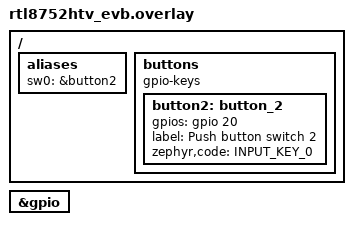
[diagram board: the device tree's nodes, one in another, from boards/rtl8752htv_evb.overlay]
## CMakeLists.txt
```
# SPDX-License-Identifier: Apache-2.0

cmake_minimum_required(VERSION 3.20.0)

find_package(Zephyr REQUIRED HINTS $ENV{ZEPHYR_BASE})
project(pad_wakeup_dlps)

FILE(GLOB app_sources src/*.c)
target_sources(app PRIVATE ${app_sources})
```

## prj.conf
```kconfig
CONFIG_PM=y
CONFIG_PM_DEVICE=y
CONFIG_PM_POLICY_CUSTOM=n # use zephyr pm flow, enable this config; use realtek pm flow, disable this config.
CONFIG_RUNTIME_NMI=y # customize NMI for Power Manager
CONFIG_REALTEK_USING_SDK_LIB=y
CONFIG_GPIO=y
CONFIG_ZTEST=y
```

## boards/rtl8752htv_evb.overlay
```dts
#include <zephyr/dt-bindings/input/input-event-codes.h>
/ {
	aliases {
		sw0 = &button2;
	};
    buttons {
		compatible = "gpio-keys";
		button2: button_2 {
			gpios = <&gpio 20 (GPIO_PULL_UP|GPIO_ACTIVE_HIGH)>;
			label = "Push button switch 2";
			zephyr,code = <INPUT_KEY_0>;
		};
	};
};

&gpio {
	status = "okay";
};
```

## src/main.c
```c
/*
 * Copyright (c) 2025 Realtek Semiconductor Corp.
 *
 * SPDX-License-Identifier: Apache-2.0
 */

#include <zephyr/kernel.h>
#include <zephyr/drivers/gpio.h>
#include <zephyr/ztest.h>

#if (CONFIG_SOC_SERIES_RTL8752H) /* CONFIG_SOC_SERIES_RTL8752H */
#include <zephyr/dt-bindings/gpio/realtek-bee-gpio.h>
#include <dlps.h>
#include <trace.h>
#include <rtl876x_pinmux.h>
#define power_get_statistics platform_pm_get_statistics
#else
#include <zephyr/dt-bindings/gpio/realtek-rtl87x2g-gpio.h>
#include <pm.h>
#endif

#define KEY_PRESS_NUMBERS 5
static uint32_t key_press_num;

static struct k_sem test_thread_sem;

static uint32_t wakeup_count_before_test;
static uint32_t wakeup_count_after_test;
static uint32_t last_wakeup_clk, last_sleep_clk;

#if DT_NODE_EXISTS(DT_NODELABEL(button2))
#define BUTTON DT_NODELABEL(button2)
#endif

#if DT_NODE_EXISTS(BUTTON)
#define BUTTON_DEV   DT_PHANDLE(BUTTON, gpios)
#define BUTTON_PIN   DT_PHA(BUTTON, gpios, pin)
#define BUTTON_FLAGS DT_PHA(BUTTON, gpios, flags)

static const struct device *const button_dev = DEVICE_DT_GET(BUTTON_DEV);

static struct k_work button_work;

static void button_cb(const struct device *port, struct gpio_callback *cb, gpio_port_pins_t pins)
{
	DBG_DIRECT("button_cb");
	k_work_submit(&button_work);
}
#endif /* BUTTON */

static void button_pressed(struct k_work *work)
{
	key_press_num++;
	printk("button press tested, key_press_num:%d!\n", key_press_num);
	if (key_press_num == KEY_PRESS_NUMBERS) {
		k_sem_give(&test_thread_sem);
	}
}

ZTEST(pad_wakeup_dlps, test_gpio_wakeup_dlps)
{
	printk("Starting gpio_wakeup_dlps Test\n");
	k_work_init(&button_work, button_pressed);
	int err;

	err = gpio_pin_configure(button_dev, BUTTON_PIN,
				 BUTTON_FLAGS | GPIO_INPUT | GPIO_PULL_UP | GPIO_ACTIVE_LOW |
					 BEE_GPIO_INPUT_PM_WAKEUP | BEE_GPIO_INPUT_DEBOUNCE_MS(1));

	if (err) {
		TC_PRINT("gpio_pin_configure err!");
	}

	static struct gpio_callback gpio_cb;
	/* GPIO_INT_EDGE_TO_ACTIVE:When dlps is turned on, multiple groups will be triggered
	 * repeatedly, and when dlps
	 * is turned off, it is normal; Debounce has no improvement.
	 *
	 * err = gpio_pin_interrupt_configure(button_dev, BUTTON_PIN, GPIO_INT_EDGE_TO_ACTIVE);
	 */
	err = gpio_pin_interrupt_configure(button_dev, BUTTON_PIN, GPIO_INT_LEVEL_ACTIVE);
	System_WakeUpPinEnable(P2_4, PAD_WAKEUP_POL_LOW, 0, 0);

	if (err) {
		TC_PRINT("gpio_pin_interrupt_configure err!");
	}

	gpio_init_callback(&gpio_cb, button_cb, BIT(BUTTON_PIN));
	gpio_add_callback(button_dev, &gpio_cb);

	power_get_statistics(&wakeup_count_before_test, &last_wakeup_clk, &last_sleep_clk);
	printk("Please press KEY2 %d times!\n", KEY_PRESS_NUMBERS);
	k_sem_init(&test_thread_sem, 0, UINT_MAX);
	k_sem_take(&test_thread_sem, K_FOREVER);
	power_get_statistics(&wakeup_count_after_test, &last_wakeup_clk, &last_sleep_clk);
	uint32_t wakeup_count_key_press = wakeup_count_after_test - wakeup_count_before_test;

	TC_PRINT("wakeupCount: %d, last_wakeup_clk:%d, last_sleep_clk:%d\n", wakeup_count_key_press,
		 last_wakeup_clk, last_sleep_clk);

	zassert_true(wakeup_count_key_press == KEY_PRESS_NUMBERS,
		     "test_gpio_wakeup_dlps failed, wakeup Count: %d\n", wakeup_count_key_press);
}

void teardown_fn(void *data)
{
	lps_mode_pause();
}

ZTEST_SUITE(pad_wakeup_dlps, NULL, NULL, NULL, NULL, teardown_fn);
```
